# S32K118_M0P register map
Vendor: NXP Semiconductors; File version: 1.1
S32K118_M0P NXP Microcontroller
CPU: CM0PLUS r0p0, little endian, MPU, FPU, VTOR, 4 interrupt priority bits
Registers are 32-bit, read-write, reset 0x0 unless marked. A register's access mark holds for its fields unless they carry their own. Offsets are from the block's base; lines under a group give offsets from that group; [hi:lo] are bit positions; {n}, {i} and the like mark numbered series; 'fields as' and 'values as' point back to an identical list; <NAME> marks a mode.

## Memory map
0x40000000 AIPS size 0x70
0x40001000 MSCM size 0x40C
0x40008000 DMA size 0x1080
0x4000D000 MPU size 0x820
0x40018000 ERM size 0x104
0x40019000 EIM size 0x108
0x40020000 FTFC size 0x30
0x40021000 DMAMUX size 0x4
0x40024000 FLEXCAN0 size 0xC0C — CAN
0x4002C000 LPSPI0 size 0x78 — LPSPI
0x4002D000 LPSPI1 size 0x78 — LPSPI
0x40032000 CRC size 0xC
0x40036000 PDB0 size 0x198 — Programmable Delay Block
0x40037000 LPIT0 size 0x5C — LPIT
0x40038000 FTM0 size 0xBC — FTM
0x40039000 FTM1 size 0x224 — FTM
0x4003B000 ADC0 size 0xEC — ADC
0x4003D000 RTC size 0x20
0x4003E000 CMU0 size 0x18 — CMU_FC
0x4003F000 CMU1 size 0x18 — CMU_FC
0x40040000 LPTMR0 size 0x10 — LPTMR
0x40048000 SIM size 0x70
0x40049000 PORTA size 0xCC — Pin Control and Interrupts
0x4004A000 PORTB size 0xCC — Pin Control and Interrupts
0x4004B000 PORTC size 0xCC — Pin Control and Interrupts
0x4004C000 PORTD size 0xCC — Pin Control and Interrupts
0x4004D000 PORTE size 0xCC — Pin Control and Interrupts
0x40052000 WDOG size 0x10
0x4005A000 FLEXIO size 0x510
0x40063000 TRGMUX size 0x68
0x40064000 SCG size 0x30C — System Clock Generator
0x40065000 PCC size 0x1D0
0x40066000 LPI2C0 size 0x174 — LPI2C
0x4006A000 LPUART0 size 0x30 — LPUART
0x4006B000 LPUART1 size 0x30 — LPUART
0x40073000 CMP0 size 0xC — High-Speed Comparator (CMP), Voltage Reference (VREF) Digital-to-Analog Converter (DAC), and Analog Mux (ANMUX)
0x4007D000 PMC size 0x5
0x4007E000 SMC size 0x18 — System Mode Controller
0x4007F000 RCM size 0x20 — Reset Control Module
0x400FF000 PTA size 0x18 — GPIO
0x400FF040 PTB size 0x18 — GPIO
0x400FF080 PTC size 0x18 — GPIO
0x400FF0C0 PTD size 0x18 — GPIO
0x400FF100 PTE size 0x18 — GPIO
0xF0001000 MTB_DWT size 0x1000 — MTB data watchpoint and trace
0xF0003000 MCM size 0x4A8 — Core Platform Miscellaneous Control Module

## ERM
Base 0x40018000
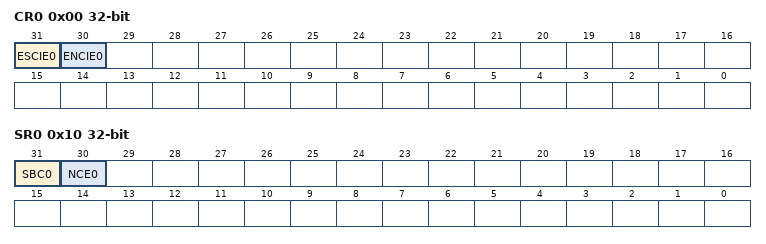
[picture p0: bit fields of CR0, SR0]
0x00 CR0 — ERM Configuration Register 0
  [31] ESCIE0
    0=Interrupt notification of Memory 0 single-bit correction events is disabled; 1=Interrupt notification of Memory 0 single-bit correction events is enabled
  [30] ENCIE0
    0=Interrupt notification of Memory 0 non-correctable error events is disabled; 1=Interrupt notification of Memory 0 non-correctable error events is enabled
0x10 SR0 write-1-clears — ERM Status Register 0
  [31] SBC0 write-1-clears
    0=No single-bit correction event on Memory 0 detected; 1=Single-bit correction event on Memory 0 detected
  [30] NCE0 write-1-clears
    0=No non-correctable error event on Memory 0 detected; 1=Non-correctable error event on Memory 0 detected
0x100 EAR0 ro — ERM Memory n Error Address Register
  [31:0] EAR

## EIM
Base 0x40019000
0x00 EIMCR — Error Injection Module Configuration Register
  [0] GEIEN — Global Error Injection Enable
    0=Disabled; 1=Enabled
0x04 EICHEN — Error Injection Channel Enable register
  [31] EICH0EN — Error Injection Channel 0 Enable
    0=Error injection is disabled on Error Injection Channel 0; 1=Error injection is enabled on Error Injection Channel 0
0x100 EICHD0_WORD0 — Error Injection Channel Descriptor n, Word0
  [31:25] CHKBIT_MASK — Checkbit Mask
0x104 EICHD0_WORD1 — Error Injection Channel Descriptor n, Word1
  [31:0] B0_3DATA_MASK — Data Mask Bytes 0-3

## Licence text in the file
Copyright 2016-2022 NXP NXP Confidential. This software is owned or controlled by NXP and may only be used strictly in accordance with the applicable license terms. By expressly accepting such terms or by downloading, installing, activating and/or otherwise using the software, you are agreeing that you have read, and that you agree to comply with and are bound by, such license terms. If you do not agree to be bound by the applicable license terms, then you may not retain, install, activate or otherwise use the software. The production use license in Section 2.3 is expressly granted for this software.
